# GD32M53x register map
File version: 1.0
CPU: CM33 r2p1, little endian, MPU, FPU, DSP, 4 interrupt priority bits
Registers are 32-bit, read-write, reset 0x0 unless marked. A register's access mark holds for its fields unless they carry their own. Offsets are from the block's base; [hi:lo] are bit positions; {n}, {i} and the like mark numbered series.

## TIMER1 — General level 0 timer
Base 0x40014000
Same registers: TIMER2 0x40014400
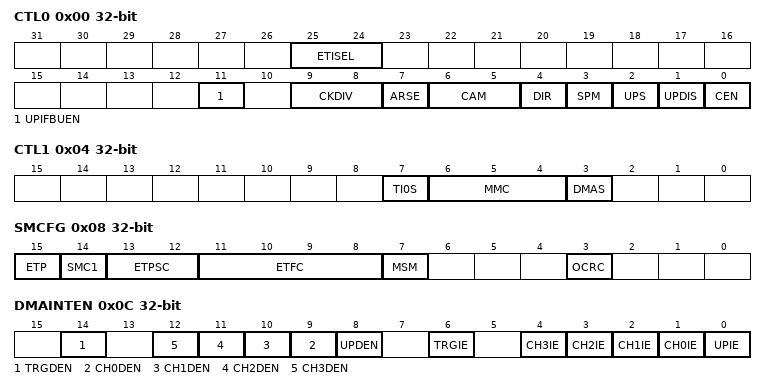
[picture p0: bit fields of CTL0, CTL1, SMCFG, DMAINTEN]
0x00 CTL0 — Control register 0
  [25:24] ETISEL — timer external trigger input signal select
  [11] UPIFBUEN — upif bit backup enable
  [9:8] CKDIV — clock division
  [7] ARSE — auto-reload shadow enable
  [6:5] CAM — counter align mode selection
  [4] DIR — direction
  [3] SPM — single pulse mode
  [2] UPS — update source
  [1] UPDIS — update disable
  [0] CEN — counter enable
0x04 CTL1 — Control register 1
  [7] TI0S — channel 0 trigger input selection
  [6:4] MMC — master mode control
  [3] DMAS — dma request source selection
0x08 SMCFG — Slave mode configuration register
  [15] ETP — external trigger polarity
  [14] SMC1 — part of slave mode controller is used to enable external clock mode 1
  [13:12] ETPSC — external trigger prescaler
  [11:8] ETFC — external trigger filter control
  [7] MSM — master-slave mode
  [3] OCRC
0x0C DMAINTEN — DMA and interrupt enable register
  [14] TRGDEN — trigger dma request enable
  [n+9] CH{n}DEN (n=0..3) — channel {n} capture/compare dma request enable
  [8] UPDEN — update dma request enable
  [6] TRGIE — trigger interrupt enable
  [n+1] CH{n}IE (n=0..3) — channel {n} capture/compare interrupt enable
  [0] UPIE — update interrupt enable
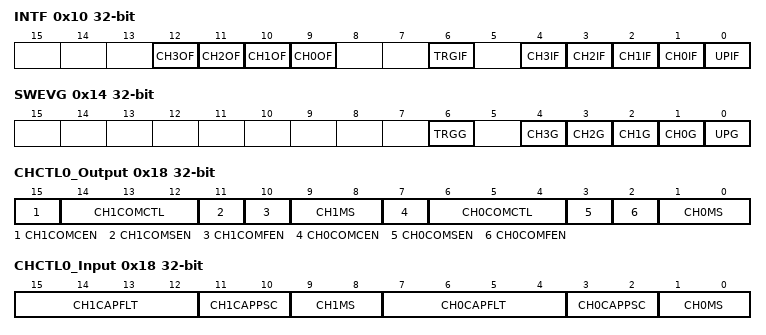
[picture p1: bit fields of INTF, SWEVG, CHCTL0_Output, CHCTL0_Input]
0x10 INTF — Interrupt flag register
  [n+9] CH{n}OF (n=0..3) — channel {n} over capture flag
  [6] TRGIF — trigger interrupt flag
  [n+1] CH{n}IF (n=0..3) — channel {n} capture/compare interrupt flag
  [0] UPIF — update interrupt flag
0x14 SWEVG wo — Software event generation register
  [6] TRGG — trigger event generation
  [n+1] CH{n}G (n=0..3) — channel {n} capture or compare event generation
  [0] UPG — update event generation
0x18 CHCTL0_Output — Channel control register 0 (output mode)
  [15] CH1COMCEN — channel 1 output compare clear enable
  [14:12] CH1COMCTL — channel 1 compare output control
  [11] CH1COMSEN — channel 1 output compare shadow enable
  [10] CH1COMFEN — channel 1 output compare fast enable
  [9:8] CH1MS — channel 1 mode selection
  [7] CH0COMCEN — channel 0 output compare clear enable
  [6:4] CH0COMCTL — channel 0 compare output control
  [3] CH0COMSEN — channel 0 compare output shadow enable
  [2] CH0COMFEN — channel 0 output compare fast enable
  [1:0] CH0MS — channel 0 i/o mode selection
0x18 CHCTL0_Input (alternate view of CHCTL0_Output) — Channel control register 0 (input mode)
  [15:12] CH1CAPFLT — Channel 1 input capture filter control
  [11:10] CH1CAPPSC — Channel 1 input capture prescaler
  [9:8] CH1MS — Channel 1 mode selection
  [7:4] CH0CAPFLT — Channel 0 input capture filter control
  [3:2] CH0CAPPSC — Channel 0 input capture prescaler
  [1:0] CH0MS — Channel 0 I/O mode selection
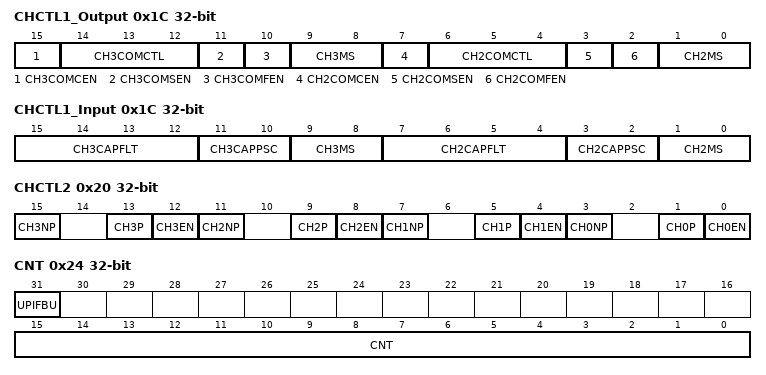
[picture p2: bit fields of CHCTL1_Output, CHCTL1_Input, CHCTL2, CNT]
0x1C CHCTL1_Output — Channel control register 1 (output mode)
  [15] CH3COMCEN — channel 3 output compare clear enable
  [14:12] CH3COMCTL — channel 3 compare output control
  [11] CH3COMSEN — channel 3 output compare shadow enable
  [10] CH3COMFEN — channel 3 output compare fast enable
  [9:8] CH3MS — channel 3 i/o mode selection
  [7] CH2COMCEN — channel 2 output compare clear enable
  [6:4] CH2COMCTL — channel 2 compare output control
  [3] CH2COMSEN — channel 2 compare output shadow enable
  [2] CH2COMFEN — channel 2 output compare fast enable
  [1:0] CH2MS — channel 2 i/o mode selection
0x1C CHCTL1_Input (alternate view of CHCTL1_Output) — Channel control register 1 (input mode)
  [15:12] CH3CAPFLT — Channel 3 input capture filter control
  [11:10] CH3CAPPSC — Channel 3 input capture prescaler
  [9:8] CH3MS — Channel 3 mode selection
  [7:4] CH2CAPFLT — Channel 2 input capture filter control
  [3:2] CH2CAPPSC — Channel 2 input capture prescaler
  [1:0] CH2MS — Channel 2 I/O mode selection
0x20 CHCTL2 — Channel control register 2
  [4n+3] CH{n}NP (n=0..3) — channel {n} complementary capture polarity
  [4n+1] CH{n}P (n=0..3) — channel {n} capture/compare function polarity
  [4n] CH{n}EN (n=0..3) — channel {n} capture/compare function enable
0x24 CNT access per field — Counter register
  [31] UPIFBU ro — upif bit backup
  [15:0] CNT rw — this bit-field indicates the current counter value
0x28 PSC — Prescaler register
  [15:0] PSC — prescaler value of the counter clock
0x2C CAR — Counter auto reload register
  [15:0] CARL — counter auto reload value
0x34 CH0CV — Channel 0 capture/compare value register
  [15:0] CH0VAL — capture/compare value of channel0
0x38 CH1CV — Channel 1 capture/compare value register
  [15:0] CH1VAL — capture/compare value of channel1
0x3C CH2CV — Channel 2 capture/compare value register
  [15:0] CH2VAL — capture/compare value of channel 2
0x40 CH3CV — Channel 3 capture/compare value register
  [15:0] CH3VAL — capture/compare value of channel 3
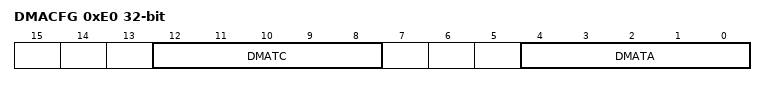
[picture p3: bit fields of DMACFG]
0xE0 DMACFG — DMA configuration register
  [12:8] DMATC — dma transfer count
  [4:0] DMATA — dma transfer access start address
0xE4 DMATB — DMA transfer buffer register
  [31:0] DMATB — dma transfer buffer
0xFC CFG — Configuration register
  [1] CHVSEL — write chxval register selection bit
